# USB0_COMMON_0_VBP2APB_WRAP_CONTROLLER_VBP_CORE_ADDR_MAP register map
Vendor: Texas Instruments
Registers are 32-bit, access per field, reset 0x0 unless marked. A register's access mark holds for its fields unless they carry their own. Offsets are as the file gives them; [hi:lo] are bit positions.

## USB0_COMMON_0_VBP2APB_WRAP_CONTROLLER_VBP_CORE_ADDR_MAP (part 3 of 8)
0x14 VBP2APB_WRAP__CONTROLLER_VBP__CORE_ADDR_MAP_RSVD_6_ASF ro
0x14 VBP2APB_WRAP__CONTROLLER_VBP__CORE_ADDR_MAP_DBOFF ro reset 0x3000
  [31:2] DAO — Doorbell Array Offset, RO. Default = implementation dependent. This field defines the offset in Dwords of the Doorbell Array base address from the Base [i.e. the base address of the xHCI Capability register address space].
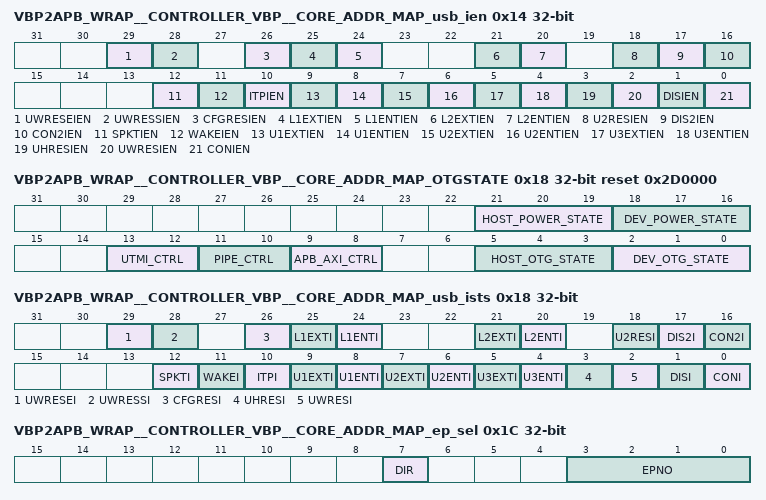
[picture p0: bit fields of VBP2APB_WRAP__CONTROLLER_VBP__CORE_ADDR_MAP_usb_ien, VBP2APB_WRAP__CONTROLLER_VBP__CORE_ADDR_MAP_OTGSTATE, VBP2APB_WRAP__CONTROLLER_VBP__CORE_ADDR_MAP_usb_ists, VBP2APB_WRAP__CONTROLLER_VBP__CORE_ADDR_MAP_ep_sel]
0x14 VBP2APB_WRAP__CONTROLLER_VBP__CORE_ADDR_MAP_usb_ien
  [29] UWRESEIEN rw — End of the USB SS warm reset interrupt enable. This bit enables requesting a UWRESEI interrupt
  [28] UWRESSIEN rw — Start of the USB SS warm reset interrupt enable. This bit enables requesting a UWRESSI interrupt
  [26] CFGRESIEN rw — Configuration reset interrupt enable. This bit enables requesting a CFGRESI interrupt
  [25] L1EXTIEN rw — LPM L1 state exit interrupt enable. This bit enables requesting an L1EXTI interrupt.
  [24] L1ENTIEN rw — LPM L1 state enter interrupt enable. This bit enables requesting an L1ENTI interrupt.
  [21] L2EXTIEN rw — LPM L2 state exit interrupt enable. This bit enables requesting a L2EXTI interrupt.
  [20] L2ENTIEN rw — LPM L2 state enter interrupt enable. This bit enables requesting a L2ENTI interrupt.
  [18] U2RESIEN rw — USB reset [HS/FS mode] interrupt enable. This bit enables requesting an U2RESI interrupt.
  [17] DIS2IEN rw — HS/FS mode disconnection interrupt enable. This bit enables requesting a DIS2I interrupt.
  [16] CON2IEN rw — HS/FS mode connection interrupt enable. This bit enables requesting a CON2I interrupt.
  [12] SPKTIEN rw — Send Custom Packet interrupt enable. This bit enables requesting a Send Custom Packet interrupt.
  [11] WAKEIEN rw — Wakeup interrupt enable. This bit enables requesting a Wakeup interrupt.
  [10] ITPIEN rw — ITP/SOF packet detected interrupt enable. This bit enables requesting an ITPI interrupt.
  [9] U1EXTIEN rw — SS link U1 state exit interrupt enable. This bit enables requesting an U1EXTI interrupt.
  [8] U1ENTIEN rw — SS link U1 state enter interrupt enable. This bit enables requesting an U1ENTI interrupt.
  [7] U2EXTIEN rw — SS link U2 state exit interrupt enable. This bit enables requesting an U2EXTI interrupt.
  [6] U2ENTIEN rw — SS link U2 state enter interrupt enable. This bit enables requesting an U2ENTI interrupt.
  [5] U3EXTIEN rw — SS link U3 state exit interrupt enable [wakeup]. This bit enables requesting an U3EXTI interrupt.
  [4] U3ENTIEN rw — SS link U3 state enter interrupt enable [suspend]. This bit enables requesting an U3ENTI interrupt.
  [3] UHRESIEN rw — USB SS hot reset interrupt enable. This bit enables requesting an UHRESI interrupt.
  [2] UWRESIEN rw — USB SS warm reset interrupt enable. This bit enables requesting an UWRESI interrupt.
  [1] DISIEN rw — SS disconnection interrupt enable. This bit enables requesting a DISI interrupt.
  [0] CONIEN rw — SS connection interrupt enable. This bit enables requesting a CONI interrupt.
0x18 VBP2APB_WRAP__CONTROLLER_VBP__CORE_ADDR_MAP_OTGSTATE ro reset 0x2D0000
  [21:19] HOST_POWER_STATE — Current state of the Host power controlling FSM: 3'b000 : POWER_IDLE 3'b001 : POWER_OFF_ACK 3'b010 : POWER_OFF_MAIN_ACK 3'b011 : POWER_OFF 3'b100 : POWER_ON_REQ 3'b101 : POWER_ISO_DIS 3'b110 : POWER_ON 3'b111 : POWER_ON_READY
  [18:16] DEV_POWER_STATE — Current state of the Device power controlling FSM: 3'b000 : POWER_IDLE 3'b001 : POWER_OFF_ACK 3'b010 : POWER_OFF_MAIN_ACK 3'b011 : POWER_OFF 3'b100 : POWER_ON_REQ 3'b101 : POWER_ISO_DIS 3'b110 : POWER_ON 3'b111 : POWER_ON_READY
  [13:12] UTMI_CTRL — Current state of the USB2 UTMI mux selector. 2'b00 : Both modes off. OTG takes control over UTMI [SRP,BC] 2'b01 : Host active. 2'b10 : Device active. 2'b11 : Illegal [both modes off]
  [11:10] PIPE_CTRL — Current state of the USB3 PIPE mux selector. 2'b00 : Both modes off. 2'b01 : Host active. 2'b10 : Device active. 2'b11 : Illegal [both modes off]
  [9:8] APB_AXI_CTRL — Current state of the ABP/AXI mux selector. 2'b00 : Both modes off. 2'b01 : Host active. 2'b10 : Device active. 2'b11 : Illegal [both modes off]
  [5:3] HOST_OTG_STATE — Current state of the OTG Host FSM. 3'b000 : H_IDLE 3'b001 : H_VBUS_ON 3'b010 : H_VBUS_FAILED 3'b011 : H_OTG_HOST_MODE 3'b100 : H_HOST_MODE 3'b101 : H_SWITCH_TO_DEVICE 3'b110 : H_A_SUSPEND 3'b111 : H_WAIT_VBUS_FALL
  [2:0] DEV_OTG_STATE — Current state of the OTG Device FSM. 3'b000 : DEV_IDLE 3'b001 : DEV_MODE 3'b010 : DEV_SRP 3'b011 : DEV_WAIT_VBUS_FALL 3'b100 : DEV_SWITCH_TO_HOST 3'b101 : DEV_WAIT_FOR_CONN
0x18 VBP2APB_WRAP__CONTROLLER_VBP__CORE_ADDR_MAP_RSVD_7_ASF ro
0x18 VBP2APB_WRAP__CONTROLLER_VBP__CORE_ADDR_MAP_RTSOFF ro reset 0x2000
  [31:5] RRSO — Runtime Register Space Offset, RO. Default = implementation dependent. This field defines the 32-byte offset of the xHCI Runtime Registers from the Base. i.e. Runtime Register Base Address = Base + Runtime Register Set Offset.
0x18 VBP2APB_WRAP__CONTROLLER_VBP__CORE_ADDR_MAP_usb_ists access not given
  [29] UWRESEI — End of the USB warm reset detected. This interrupt is requested after the SuperSpeed warm reset ends. This interrupt is reported on the irqs[0] pin. (access R/W1TC)
  [28] UWRESSI — Start of the USB warm reset detected. This interrupt is requested as soon as the SuperSpeed warm reset signalling is detected. This interrupt is reported on the irqs[0] pin. (access R/W1TC)
  [26] CFGRESI — USB configuration reset detected. This interrupt is requested after the device internally resets its endpoints onfiguration. This is done after each USB reset [UWRESI, UWRESI or U2RESI], after each connection event [CONI, CON2I] and after configuration reset initiated by software [USB_CONF.CFGRST]. Generally this interrupt is generated in the same time as mentioned interrupts, however due to internal clock domain synchronisation this configuration reset can be performed a little later, so one can use this interrupt to perform some software operations. This interrupt informs that controller did the following operations: disabled all non control endpoints, cleared all pending endpoints transfers and interrupts. The configuration reset does not clear general device configuration [set in USB_CONF] and EP0 configuration settings. This interrupt is reported on the irqs[0] pin. (access R/W1TC)
  [25] L1EXTI — LPM L1 state exit detected This interrupt informs that HS/FS LPM exit L1 state. This interrupt is reported on the irqs[0] pin. (access R/W1TC)
  [24] L1ENTI — LPM L1 state enter detected This interrupt informs that HS/FS LPM enter L1 state. This interrupt is reported on the irqs[0] pin. (access R/W1TC)
  [21] L2EXTI — LPM L2 state exit detected This interrupt informs that HS/FS LPM exit L2 state. This interrupt is reported on the irqs[1] pin. (access R/W1TC)
  [20] L2ENTI — LPM L2 state enter detected This interrupt informs that HS/FS LPM enter L2 state. This interrupt is reported on the irqs[0] pin. (access R/W1TC)
  [18] U2RESI — USB reset [HS/FS mode] detected This interrupt is requested after the USB reset in HS/FS mode ends. This interrupt is reported on the irqs[0] pin. (access R/W1TC)
  [17] DIS2I — HS/FS mode disconnection detected This interrupt informs that HS/FS upstream port was disconncted from the USB line. This interrupt is reported on the irqs[0] pin. (access R/W1TC)
  [16] CON2I — HS/FS mode connection detected This interrupt informs that HS/FS upstream port was conncted to the USB line This interrupt is reported on the irqs[0] pin. (access R/W1TC)
  [12] SPKTI — Send Custom Packet This interrupt informs that Custom Packet prepared in the USB_CPKT1-3 registers and triggered with USB_CMD.SPKT bit was already sent. This interrupt is reported on the irqs[0] pin. (access R/W1TC)
  [11] WAKEI — This interrupt informs that at wakeup pin appeared active state. This interrupt is reported on the irqs[1] pin. (access R/W1TC)
  [10] ITPI — ITP/SOF packet detected In SuperSpeed mode this interrupt informs that ITP packet was received. In FS/HS mode this interrupt informs that SOF was detected. This interrupt is reported on the irqs[0] pin. (access R/W1TC)
  [9] U1EXTI — SS link U1 state exit detected This interrupt informs that SuperSpeed link exit U1 state. This interrupt is reported on the irqs[0] pin. (access R/W1TC)
  [8] U1ENTI — SS link U1 state enter detected This interrupt informs that SuperSpeed link enter U1 state. This interrupt is reported on the irqs[0] pin. (access R/W1TC)
  [7] U2EXTI — SS link U2 state exit detected This interrupt informs that SuperSpeed link exit U2 state. This interrupt is reported on the irqs[0] pin. (access R/W1TC)
  [6] U2ENTI — SS link U2 state enter detected This interrupt informs that SuperSpeed link enter U2 state. This interrupt is reported on the irqs[0] pin. (access R/W1TC)
  [5] U3EXTI — SS link U3 state exit detected [wakeup] This interrupt informs that SuperSpeed link exit U3 state. This interrupt is reported on the irqs[1] pin. (access R/W1TC)
  [4] U3ENTI — SS link U3 state enter detected [suspend] This interrupt informs that SuperSpeed link enter U3 state. This interrupt is reported on the irqs[0] pin. (access R/W1TC)
  [3] UHRESI — USB SS hot reset detected This interrupt is requested after the SuperSpeed hot reset ends. This interrupt is reported on the irqs[0] pin. (access R/W1TC)
  [2] UWRESI — USB SS warm reset detected This interrupt is requested after the SuperSpeed warm reset ends or when USBSS-DEVs LTSSM exits Polling.LFPS state. After this reset, SW should reininitialize the controller. This interrupt is reported on the irqs[0] pin. (access R/W1TC)
  [1] DISI — SS disconnection detected This interrupt informs that SuperSpeed link was disconncted from the USB line. This interrupt is reported on the irqs[0] pin. (access R/W1TC)
  [0] CONI — SS connection detected This interrupt informs that SuperSpeed link was conncted to the USB line This interrupt is reported on the irqs[0] pin. (access R/W1TC)
0x1C VBP2APB_WRAP__CONTROLLER_VBP__CORE_ADDR_MAP_RSVD_8_ASF ro
0x1C VBP2APB_WRAP__CONTROLLER_VBP__CORE_ADDR_MAP_HCCPARAMS2 ro reset 0x8
  [3] CTC — This bit indicates whether the xHC USB3 Root Hub ports support the Compliance Transition Enabled [CTE] flag. When this bit is 1 USB3 Root Hub port state machine transitions to the Compliance substate shall be explicitly enabled software. When this bit is 0. USB3 Root Hub port state machine transitions to the Compliance substate are automatically enabled.
0x1C VBP2APB_WRAP__CONTROLLER_VBP__CORE_ADDR_MAP_ep_sel
  [7] DIR rw — Selected Endpoint direction. 0-OUT Endpoint selected, 1-IN Endpoint selected
  [3:0] EPNO rw — Selected Endpoint number
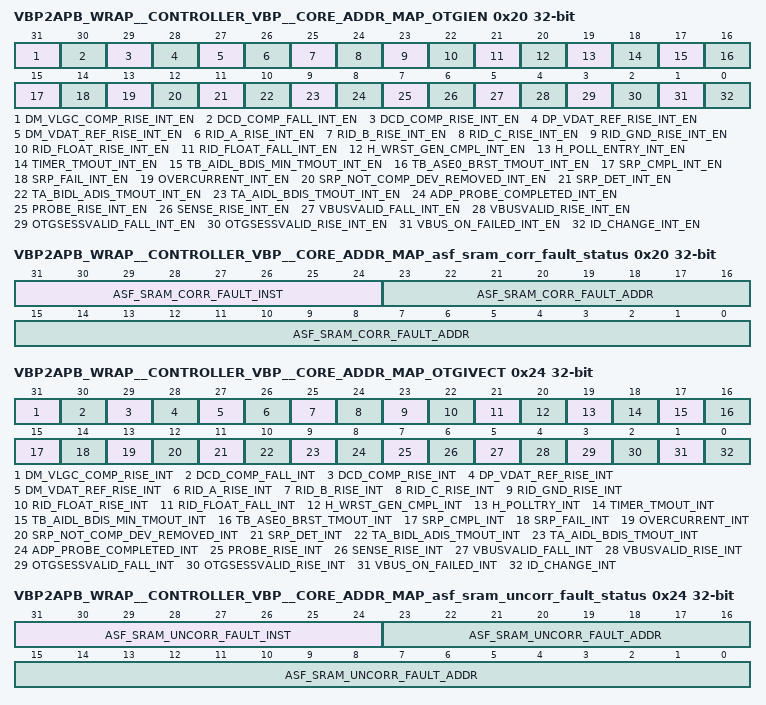
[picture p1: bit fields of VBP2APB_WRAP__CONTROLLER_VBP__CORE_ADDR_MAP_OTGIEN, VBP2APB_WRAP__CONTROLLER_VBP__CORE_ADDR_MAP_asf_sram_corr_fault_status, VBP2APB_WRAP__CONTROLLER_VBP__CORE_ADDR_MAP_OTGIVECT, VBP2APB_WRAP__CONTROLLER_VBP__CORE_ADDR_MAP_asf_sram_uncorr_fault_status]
0x20 VBP2APB_WRAP__CONTROLLER_VBP__CORE_ADDR_MAP_OTGIEN rw
  [31] DM_VLGC_COMP_RISE_INT_EN — DM VLGC comparator rise detect interrupt enable
  [30] DCD_COMP_FALL_INT_EN — DCD comparator fall detect interrupt enable
  [29] DCD_COMP_RISE_INT_EN — DCD comparator rise detect interrupt enable
  [28] DP_VDAT_REF_RISE_INT_EN — DP VDAT comparator rise detect interrupt enable
  [27] DM_VDAT_REF_RISE_INT_EN — DM VDAT comparator rise detect interrupt enable
  [26] RID_A_RISE_INT_EN — RID A comparator rise detect interrupt enable
  [25] RID_B_RISE_INT_EN — RID B comparator rise detect interrupt enable
  [24] RID_C_RISE_INT_EN — RID C comparator rise detect interrupt enable
  [23] RID_GND_RISE_INT_EN — RID GND comparator rise detect interrupt enable
  [22] RID_FLOAT_RISE_INT_EN — RID floating comparator rise detect interrupt enable
  [21] RID_FLOAT_FALL_INT_EN — RID floating comparator detect interrupt enable
  [20] H_WRST_GEN_CMPL_INT_EN — Host Warm Reset generation completed interrupt enable.
  [19] H_POLL_ENTRY_INT_EN — Host Polling state entry interrupt enable.
  [18] TIMER_TMOUT_INT_EN — Timer timeout interrupt enable.
  [17] TB_AIDL_BDIS_MIN_TMOUT_INT_EN — The bus has been in Idle state for the required time during HNP interrupt enable.
  [16] TB_ASE0_BRST_TMOUT_INT_EN — No response from A-Device to HNP interrupt enable.
  [15] SRP_CMPL_INT_EN — SRP completed interrupt enable.
  [14] SRP_FAIL_INT_EN — No response from SRP from A-Device interrupt enable.
  [13] OVERCURRENT_INT_EN — Overcurrent condition detected interrupt enable.
  [12] SRP_NOT_COMP_DEV_REMOVED_INT_EN — Non cmpliant device disconnect interrupt enable
  [11] SRP_DET_INT_EN — SRP pulse detected interrupt enable. NOTE: SRP detection can be enabled only if core is enabled to work as a A-device [OTGSTS.OTG_MODE=0]
  [10] TA_BIDL_ADIS_TMOUT_INT_EN — No activity from B-Device timeout interrupt enable.
  [9] TA_AIDL_BDIS_TMOUT_INT_EN — No response from B-Device for HNP interrupt enable.
  [8] ADP_PROBE_COMPLETED_INT_EN — ADP probe completed interrupt enable
  [7] PROBE_RISE_INT_EN — ADP probe comparator rise detected interrupt enable
  [6] SENSE_RISE_INT_EN — ADP sense comparator rise detected interrupt enable
  [5] VBUSVALID_FALL_INT_EN — Vbusvalid fall detected interrupt enable.
  [4] VBUSVALID_RISE_INT_EN — Vbusvalid fall detected interrupt enable.
  [3] OTGSESSVALID_FALL_INT_EN — Otgsessvalid fall detected interrupt enable.
  [2] OTGSESSVALID_RISE_INT_EN — Otgsessvalid rise detected interrupt enable.
  [1] VBUS_ON_FAILED_INT_EN — Enabling Vbus by A-Device has failed interrupt enable.
  [0] ID_CHANGE_INT_EN — ID change interrupt enable
0x20 VBP2APB_WRAP__CONTROLLER_VBP__CORE_ADDR_MAP_asf_sram_corr_fault_status ro
  [31:24] ASF_SRAM_CORR_FAULT_INST — Last SRAM instance that generated fault.
  [23:0] ASF_SRAM_CORR_FAULT_ADDR — Last SRAM address that generated fault.
0x20 VBP2APB_WRAP__CONTROLLER_VBP__CORE_ADDR_MAP_RSVD_CR ro
0x20 VBP2APB_WRAP__CONTROLLER_VBP__CORE_ADDR_MAP_ep_traddr rw
  [31:0] TRADDR — Transfer Ring address. Address of transfer ring for endpoint selected by endpoint select register. Based on this address, DMA will fetch transfer descriptors from system memory. This register can be used as dequeue pointer. CPU can use this register [read it or write to it] only when endpoint is configured and enabled [using EP_CFG register]
0x24 VBP2APB_WRAP__CONTROLLER_VBP__CORE_ADDR_MAP_OTGIVECT access not given
  [31] DM_VLGC_COMP_RISE_INT — DM VLGC comparator rise detect interrupt (access R/W1TC)
  [30] DCD_COMP_FALL_INT — DCD comparator fall detect interrupt (access R/W1TC)
  [29] DCD_COMP_RISE_INT — DCD comparator rise detect interrupt (access R/W1TC)
  [28] DP_VDAT_REF_RISE_INT — DP VDAT comparator rise detect interrupt (access R/W1TC)
  [27] DM_VDAT_REF_RISE_INT — DM VDAT comparator rise detect interrupt (access R/W1TC)
  [26] RID_A_RISE_INT — RID A comparator rise detect interrupt (access R/W1TC)
  [25] RID_B_RISE_INT — RID B comparator rise detect interrupt (access R/W1TC)
  [24] RID_C_RISE_INT — RID C comparator rise detect interrupt (access R/W1TC)
  [23] RID_GND_RISE_INT — RID GND comparator rise detect interrupt (access R/W1TC)
  [22] RID_FLOAT_RISE_INT — RID floating comparator rise detect interrupt (access R/W1TC)
  [21] RID_FLOAT_FALL_INT — RID floating comparator detect interrupt (access R/W1TC)
  [20] H_WRST_GEN_CMPL_INT — Host Warm Reset generation completed interrupt. (access R/W1TC)
  [19] H_POLLTRY_INT — Host Polling state entry interrupt. (access R/W1TC)
  [18] TIMER_TMOUT_INT — Timer timeout interrupt. (access R/W1TC)
  [17] TB_AIDL_BDIS_MIN_TMOUT_INT — The bus has been in Idle state for the required time during HNP interrupt. (access R/W1TC)
  [16] TB_ASE0_BRST_TMOUT_INT — No response from A-Device to HNP interrupt. (access R/W1TC)
  [15] SRP_CMPL_INT — SRP completed interrupt. (access R/W1TC)
  [14] SRP_FAIL_INT — No response from SRP from A-Device interrupt. (access R/W1TC)
  [13] OVERCURRENT_INT — Overcurrent condition detected interrupt. (access R/W1TC)
  [12] SRP_NOT_COMP_DEV_REMOVED_INT — Not cmpliant device disconnect detect interrupt. (access R/W1TC)
  [11] SRP_DET_INT — SRP pulse detected interrupt. (access R/W1TC)
  [10] TA_BIDL_ADIS_TMOUT_INT — No activity from B-Device timeout interrupt. (access R/W1TC)
  [9] TA_AIDL_BDIS_TMOUT_INT — No response from B-Device for HNP interrupt. (access R/W1TC)
  [8] ADP_PROBE_COMPLETED_INT — ADP completed. Status is reported in OTGADPSTS register. (access R/W1TC)
  [7] PROBE_RISE_INT — ADP probe comparator rise detected interrupt (access R/W1TC)
  [6] SENSE_RISE_INT — ADP sense comparator rise detected interrupt (access R/W1TC)
  [5] VBUSVALID_FALL_INT — Vbusvalid fall detected interrupt. (access R/W1TC)
  [4] VBUSVALID_RISE_INT — Vbusvalid fall detected interrupt. (access R/W1TC)
  [3] OTGSESSVALID_FALL_INT — Otgsessvalid fall detected interrupt. (access R/W1TC)
  [2] OTGSESSVALID_RISE_INT — Otgsessvalid rise detected interrupt. (access R/W1TC)
  [1] VBUS_ON_FAILED_INT — Enabling Vbus by A-Device has failed. This bit should be cleared before enabling subsequent connection as host. (access R/W1TC)
  [0] ID_CHANGE_INT — ID change interrupt (access R/W1TC)
0x24 VBP2APB_WRAP__CONTROLLER_VBP__CORE_ADDR_MAP_asf_sram_uncorr_fault_status ro
  [31:24] ASF_SRAM_UNCORR_FAULT_INST — Last SRAM instance that generated fault.
  [23:0] ASF_SRAM_UNCORR_FAULT_ADDR — Last SRAM address that generated fault.
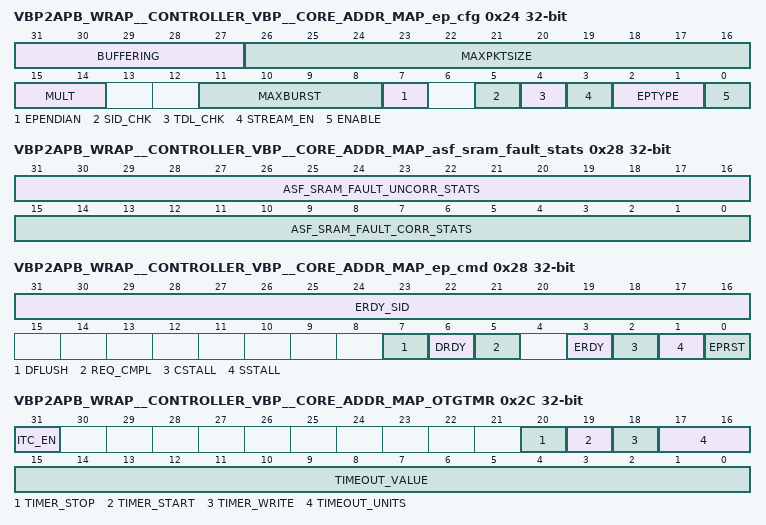
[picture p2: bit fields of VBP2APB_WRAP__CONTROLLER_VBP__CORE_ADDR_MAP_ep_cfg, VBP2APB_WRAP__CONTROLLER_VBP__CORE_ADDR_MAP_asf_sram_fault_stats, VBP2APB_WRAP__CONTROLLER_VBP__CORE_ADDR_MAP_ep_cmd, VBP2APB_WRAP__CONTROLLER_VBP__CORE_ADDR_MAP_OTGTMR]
0x24 VBP2APB_WRAP__CONTROLLER_VBP__CORE_ADDR_MAP_ep_cfg
  [31:27] BUFFERING rw — Max number of buffered packets. The maximum number of packets the device can buffer in the on-chip memory for a specified endpoint. Valid values are from 0 to 15. Value 0 means that 1 on-chip buffer is available for the appropriate endpoint. Value 15 means that 16 on-chip buffers are available for the appropriate endpoint. Each IN endpoint has individual buffers associated with it. OUT endpoints have common buffers, so buffering for OUT endpoints is determined by the maximum buffering value along all enabled OUT endpoints. The number of possible endpoint buffers depends on the on-chip memory size and the size of endpoint buffers.
  [26:16] MAXPKTSIZE rw — Max packet size. The maximum packet size this endpoint is capable of sending or receiving. SuperSpeed mode: For control endpoints, this field is set to 512. For bulk endpoint types, this field is set to 1024. For interrupt and isochronous endpoints, this field is set to 1024 if this endpoint defines a value in the bMaxBurst field greater than zero. If the value in the bMaxBurst field is set to zero, then this field can have any value from 0 to 1024 for an isochronous endpoint, and 1 to 1024 for an interrupt endpoint. High Speed/Full Speed mode: For control endpoints, this field is set to 64. For other endpoint types this field can have any value from 0 to 1024.
  [15:14] MULT rw — ISO max burst SuperSpeed mode: A zero-based value that indicates the maximum number of bursts within a service interval that this endpoint supports. This field is only valid for isochronous endpoints. A value of zero indicates that the device supports one Burst of bMaxBurst packets per service interval. The max value that can be set in this field in SuperSpeed is '2'. HS/FS mode: This field indicates how many packets will be transferred during micro frame. In Full-Speed mode only one ISO IN packet can be transferred per endpoint, per frame, thus this field has to be always '0'. In High-Speed mode, up to three ISO IN packets can be transferred per endpoint, per microframe, so the max value that can be set in this field in HighSpeed is '2'.
  [11:8] MAXBURST rw — Maximum Burst size. The maximum number of packets the endpoint can send or receive as part of a burst. Valid values are from 0 to 15. A value of 0 indicates that the endpoint can only burst one packet at a time, and a value of 15 indicates that the endpoint can burst up to 16 packets at a time. For endpoints of type control this is set to 0. This field is meaningfull only in SuperSpeed mode.
  [7] EPENDIAN rw — DMA transfer endianness. When the conversion is ON, the byte order within DWORD is inverted. While the bit is set, the software confirms that the transfer length is a multiplication of 4 bytes. Enabling the conversion is possible only when SUPPORT_ENDIANESS_CONV is defined. By default this parameter is not defined, so endianess conversion is disabled. 0: Endianess conversion OFF 1: Endianess conversion ON
  [5] SID_CHK rw — SID check[only in SS mode for BULK OUT EP] This field can be set only for SS bulk OUT endpoints with stream support enabled 1] If SID_CHK bit is set, the device checks whether the incoming packets from the host to the particular OUT endpoint have the SID field set to the expected value. If the packet has an expected SID value is then taken and stored in the on-chip device buffers. If the packet has a different SID than expected, then the packet is rejected [NRDY] and the SIDERROR interrupt is reported to the software. The value of the SID to which incoming packets will be compared, are written to the device during sending ERDY TP [EP_CMD.ERDY and EP_CMD.ERDY_SID]. The SID value from the incoming packet that has been rejected and caused the SIDERR interrupt can be read from the EP_STS_SID register. 2] If SID_CHK bit is not set, then each packet from the host is taken to the on-chip buffers is transmitted by the DMA regardless of the SID field in the TD. 0: SID chceck at device input OFF 1: SID chceck at device input ON
  [4] TDL_CHK rw — TDL check[only in SS mode for BULK OUT EP]. This field has to be set for stream capable SS bulk endpoints and it can be set for other bulk endpoint. The OUT bulk endpoints If the TDL_CHK bit is set if the device takes the packets to the OUT endpoint only when the value of the TDL [EP_CMD.TDL] for this endpoint is different from zero. Each received packet for the particular endpoint decrements the value of a TDL. If the TDL_CHK bit is not set, then each packet from the host to the OUT endpoint is taken as long as it free space in the on-chip device buffers. The IN bulk endpoints This bit is is used by USBSS_DEV to set EOB bit when TDL [programmed value] reach zero. 0: Do not check the TDL value when sending/receiving packets to the endpoints 1: Check the TDL value when sending/receiving packets to the endpoint
  [3] STREAM_EN rw — Stream support enable [only in SS mode]. This bit must be set to enable a stream transfes on a bulk endpoint 0: Stream support OFF 1: Stream support ON
  [2:1] EPTYPE rw — Endpoint type. 0: control, 1: isochronous, 2: bulk, 3: interrupt. Endpoint type is programmable, however, certain types of transmissions require hardware support that must be incorporated prior to implementation. That can be done only for selected endpoints. Selective inclusion of hardware support is to reduce the size of the controller. Accordingly: - Endpoint-type iso should be set by the software only for those endpoints for which isochronous transmission hardware support is enabled. - A bulk endpoint can handle transmission with Bulk Streams support only for those endpoints for which Bulk Stream transmission hardware support is enabled. For detailed description how to implement hardware support for ISO transfers or Bulk Stream transfers see chapter 'Endpoints Implementation'.
  [0] ENABLE rw — Endpoint enable. If endpoint is disabled [the ENABLE bit is cleared], the endpoint will not: - request any interrupts - start any transmission over the DMA Even if Endpoint is disabled, software can set DRDY bit for it, but the DMA transmission will not begin until the endpoint is enabled. 0: disabled 1: enabled Reset value of this bit for EP0 is 1, for other EP's is 0.
0x28 VBP2APB_WRAP__CONTROLLER_VBP__CORE_ADDR_MAP_CLK_FREQ reset 0x200000
  [31:16] CLK_FREQ_KHZ rw — CLK_FREQ_KHZ defines how many cycles are needed to determine 1 ms clock base for stb_clk_predft. Example: Let's say that stb_clk_predft frequency is 32kHz. With CLK_FREQ_KHZ set to 32 time base would be 32 cycles of 32khz clock which gives 1 ms
0x28 VBP2APB_WRAP__CONTROLLER_VBP__CORE_ADDR_MAP_asf_sram_fault_stats access not given
  [31:16] ASF_SRAM_FAULT_UNCORR_STATS — Count of number of uncorrectable errors if implemented. Count value will saturate at 0xffff. (access R/W1TC)
  [15:0] ASF_SRAM_FAULT_CORR_STATS — Count of number of correctable errors if implemented. Count value will saturate at 0xffff. (access R/W1TC)
0x28 VBP2APB_WRAP__CONTROLLER_VBP__CORE_ADDR_MAP_ep_cmd access not given
  [31:16] ERDY_SID rw — ERDY Stream ID value [used in SS mode]. This field contains SID - it will be sent to host in ERDY packet [by writing '1' to ERDY]. This field is meaningfull only in SuperSpeed mode.
  [7] DFLUSH rw — Data flush. Writing '1' to this bit performs the following actions for particular endpoint: - clears DRDY bit and stops DMA transfer - flush endpoint data from on chip buffers As in case of Endpoint reset [EPRST bit], after endpoint data flush the software is responsible for it to re-set the Endpoint TRADDR. When DFLUSH operation is started ['1' is written], CPU must wait until this bit becomes again '0' [it indicates that HW finishes all internal opertations related to DFLUSH], and only then can proceed with next software operations. Writing '0' has no effect.
  [6] DRDY rw — Transfer descriptor ready. Transfer Descriptor Ready for selected endpoint [0 - no effect, 1 - starts transfer]. Writing '1' to this bit informs USBSS-DEV that in-system memory has prepared a new Transfer Descriptor for selected endpoints. If an IN endpoint is 'Not Ready' [NRDY=1 in Endpoint Status Register], then setting the DRDY bit [which is proceeded by DMA transfer to the on-chip buffers] will cause the device to send the ERDY packet. If the TRB error occurs, the DRDY bit is cleared and held in the low state until the TRBERR is not cleared [even if the DTRANS bit is set i.e. the Multiple TRB chain mode is enabled]. This bit is duplicated in the Doorbell register. Writing '1' to this bit while DESCMIS interrupt flag is set for the same endpoint will also clear the DESCMIS flag.
  [5] REQ_CMPL rw — Request complete. 0 : no effect 1 : informs device that Request service is complete Bit valid only for endpoint 0. Writing '1' to this bit informs USBSS-DEV that software finished USB request service and device can send ACK answer for the Status Stage within USB request. This bit is automatically cleared by USBSS-DEV after device answers to the status stage with ACK or STALL. Until software do not set this bit, during proceeding current host request, the device will answer to the status stage with NRDY answer.
  [3] ERDY rw — Send ERDY TP. Writing '1' to this bit forces the device to send ERDY TP with stream ID equal to ERDY_SID. This bit is necessary to support SS bulk stream transfers. This bit is also used during control transfers [in both modes: HS/FS and SS]: writing '1' instruct device controller HW that it can exit from Setup Stage to the Data Stage [or directly to the Status Stage if USB Request is without Data Stage]. However the ERDY packet is only actually sent in SS mode. Writing '0' has no effect.
  [2] CSTALL — Endpoint STALL clear. Writing '1' to this bit cause the endpoint becames not halted. 0: no effect 1: clears endpoint STALL (access R/W1TC)
  [1] SSTALL rw — Endpoint STALL set. Writing '1' to this bit cause the endpoint is halted. 0: no effect 1: STALLs endpoint
  [0] EPRST rw — Endpoint reset. 0: no effect 1: resets endpoint This command performs the following actions for particular endpoint: - clears DRDY bit and stops DMA transfer - clears on-chip buffers - clears sequence number in SS mode or Data Toggle in HS/FS mode This command does not clear Endpoint interrupt if already requested [irq[0] pin was asserted] thus it is recommended first to clear all interrupts from endpoint scheduled to reset. When EPRST operation is started ['1' is written], CPU must wait until this bit becomes again '0' [it indicates that HW finishes all internal opertations related to DFLUSH], and only then can proceed with next software operations. Additionally, when DMA already started processing TD for this EP, the EPRST command cause that DMA engine will once more access the descriptor in external memory. After endpoint reset the software is responsible for it to re-set the Endpoint TRADDR. Writing '0 'has no effect.
0x2C VBP2APB_WRAP__CONTROLLER_VBP__CORE_ADDR_MAP_OTGTMR
  [31] ITC_EN wo — ITC ENABLE for device mode 0 - Device IOC and ISP interrupts moderation by OTG_IVECT interrupt from OTGTMR is disabled. 1 - The OTGTMR is used for Device IOC and ISP interrupts moderation. The OTG_IVECT from OTGTMR is not requested.
  [20] TIMER_STOP wo — Stop timer
  [19] TIMER_START wo — Start timer
  [18] TIMER_WRITE wo — Timer value and units write strobe
  [17:16] TIMEOUT_UNITS wo — Time units: 0 - hundreds of microseconds [valid only if otg controller clock is in MHz range] 1 - milliseconds 2 - tens of milliseconds 3 - hundreds of milliseconds Valid only if TIMER_WRITE is 1.
  [15:0] TIMEOUT_VALUE wo — Timeout value for timer. Valid only if TIMER_WRITE is 1.
0x2C VBP2APB_WRAP__CONTROLLER_VBP__CORE_ADDR_MAP_RSVD_12_ASF ro
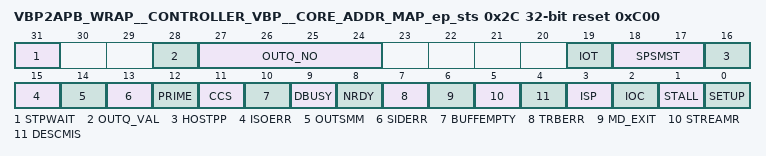
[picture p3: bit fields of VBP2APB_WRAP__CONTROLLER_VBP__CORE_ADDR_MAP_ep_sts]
0x2C VBP2APB_WRAP__CONTROLLER_VBP__CORE_ADDR_MAP_ep_sts access not given reset 0xC00
  [31] STPWAIT — Bit used only for EP0. If setup packet is received correctly and stored in the on-chip buffer, this bit is set to 1 and interrupt is generated. Setup packet is applicable only to control transmissions [EP0]. This interrupt can be masked by the corresponding bit in EP_STS_EN register. Writing '1' to this bit clears the interrupt. (access R/W1TC)
  [28] OUTQ_VAL ro — OUT queue valid flag. This field indicates whether the endpoint number of the OUT packet waiting for transmission by the DMA, is valid or not. In other words, whether the packet queue is not empty. As there is one buffers queue for all Out Endpoints, this field is not endpoint related, and thus it can be read regardless of current value stored in the EP_SEL register. 0 - queue of out packets is empty thus OUTQ_NO is not valid 1 - queue of out packets is not empty thus OUTQ_NO is valid This bit is only a status bit [not an interrupt flag].
  [27:24] OUTQ_NO ro — OUT queue endpoint number. This field shows the number of the endpoint to which the packet, received by the host, currently is waiting to be transmitted by the DMA from the on-chip buffers to the system memory. As there is one buffers queue for all Out Endpoints, this field is not endpoint related, and thus it can be read regardless of current value stored in the EP_SEL register. This bit is only a status bit [not an interrupt flag].
  [19] IOT — Interrupt On Transfer complete. This interrupt is generated when the TDL is decremented to zero. It means that the device - does not expect to have more packets from the host [OUT EP] - does not want to send more packets [IN EP] More information can be found in the description of EP_TDL register. Writing '1' to this bit clears the interrupt. (access R/W1TC)
  [18:17] SPSMST ro — Stream Protocol State Machine State [only for Bulk stream endpoints] This field is valid only for stream capable bulk endpoints and reflects the current state of the Stream Protocol State Machine for selected endpoint: 0 - DISABLED 1 - IDLE 2 - START_STREAM 3 - MOVE_DATA Soft should check if the SPSM is in IDLE state before sending ERDY TP from stream EP [leading to the transition from IDE to START_STREAM] Before software will order to send an ERDY TP from stream capable endpoint [leading to the transition from IDLE to START_STREAM] it should first check if the SPSM is in IDLE state. This bit is only a status bit [not an interrupt flag].
  [16] HOSTPP ro — Host Packet Pending [only for SS mode]. Depending on whether the endpoint is enabled for streams or not, this bit behaves as follows: 1]For stream enabled bulk endpoints [EP_CFG.EPSTREAM_EN bit set]: This bit reflects the PP bit in the last packet received from the host during Move Data state of the DOSPSM for the OUT endpoint. This bit is updated on exit from the MOVE DATA state of the DOSPSM and can be analyzed during servicing MD_EXIT interrupt for BULK OUT endpoint with Stream support enabled. If this bit is set to '0' during MD_EXIT interrupt, it means that the host terminated current stream. If this bit is set to '1' during MD_EXIT interrupt, it means that the host doesn't terminated current stream and still has data for this stream. 2]Non stream bulk endpoints [EP_CFG.EPSTREAM_EN bit not set]: This bit reflects the PP bit in the packets received from the host. This bit is updated as long as the EP_CMD.TDL is nonzero and it can be analyzed during servicing IOT interrupt for BULK endpoints. This bit is only a status bit [not an interrupt flag].
  [15] ISOERR — ISO transmission error. Error of isochronous transmission. This bit is set during data transmission to/from ISO endpoints while the last data transfer at PIPE IF is in current micro frame. For ISO IN endpoints: If host asks for data packet and device is not ready for sent data immediatelly, then ISOERR flag is set for particular endpoint and core sends a 0-length DATA packet to the host. The next data portion transfer [for the next micro frame] from system memory to on-chip buffers is automatically started [when EP_CMD.DRDY bit is set or DMA works in DMULT mode]. For ISO OUT endpoints: When host issues an OUT data packet for the specific endpoint but the OUT buffers are full, then device is unable to receive data packet and the ISOERR flag is set. For more information about ISO trasfer see chapter 'Isochronous Transfers'. This interrupt can be masked by the corresponding bit in EP_STS_EN register. Writing '1' to this bit clears the interrupt. (access R/W1TC)
  [14] OUTSMM — OUT size mismatch. This bit is set when host sends a different data size than device was anticipating [according to Data Length field in TRB]. In such a case, the DMA updates length field in current TRB, updates TRADDR [next TRB address], and triggers the interrupt. DMA will not start processing TRB ring of this EP until its DRDY is set. This interrupt can be masked by the corresponding bit in EP_STS_EN register. Writing '1' to this bit clears the interrupt. (access R/W1TC)
  [13] SIDERR — Stream error [used only in SS mode] If host requested IN [sent OUT] packet with particular Stream ID, and device is actually programmed to transfer packets with different Stream ID [SID written in the EP_CMD.ERDY_SID field] the host IN request [OUT packet] is rejected [NRDY] and the SIDERR interrupt is requested. In case of IN direction, the SIDERR interrupt will not be requested when device is not prepared for any transfer [EP_CMD.TDL= 0 for this endpoint]. In this case [and additionally when EP_CMD.DRDY= 0 and EP_STS.DBUSY=0], the DESCMIS interrupt will be requested. This interrupt can be masked by the corresponding bit in EP_STS_EN register. Writing '1' to this bit clears the interrupt. (access R/W1TC)
  [12] PRIME — Prime [used only in SS mode]. This bit is set when the device receives the packet with PRIME ID. This interrupt can be masked by the corresponding bit in EP_STS_EN register. Writing '1' to this bit clears the interrupt. (access R/W1TC)
  [11] CCS ro — Current Cycle Status. Informs about current value of C bit corresponding to DMA ownership of TRBs for selected endpoint. For more information about TRBs C bit see chapter 2.11.3. This bit is only a status bit [not an interrupt flag].
  [10] BUFFEMPTY ro — Endpoint Buffer Empty. When this bit is set to '1', there are no packets for the particular endpoint in the on-chip buffers. This bit is only a status bit [not an interrupt flag].
  [9] DBUSY ro — DMA busy. This bit is set to '1' while the DMA services the endpoint. Through the service means either actual transmission of data between on-chip cache and system memory for particular endpoint or a pending data transmission which has already begun but was interrupted by endpoint with a higher priority. Such pending transmissions will begin automatically themselves after these higher priority. This bit is only a status bit [not an interrupt flag].
  [8] NRDY — Not ready [used only in SS mode]. This bit is automatically set to 1 when for some reason endpoint enters Flow Control. If ERDY is sent automatically by the endpoint [what is done when current TDL value is greater then zero], this interrupt bit is not automatically cleared [although the endpoint itself leaves FlowControl]. Note: For BULK OUT endpoints with TDL_CHK bit seting this interrupt should be used instead of DESCMIS interrupt. See also DESCMIS description. Writing '1' to this bit clears the interrupt. (access R/W1TC)
  [7] TRBERR — TRB error. This bit is set if DMA read corrupted TRB [wrong C bit value or TRB type]. Address of the TRB is stored in the EP_TRADDR register. This interrupt can be masked by the corresponding bit in EP_STS_EN register. If this error occurs, the bit DRDY is cleared and held in the low state until the TRBERR is not cleared. To start the DMA again, the software has to clear this interrupt and set the DRDY bit once more. Writing '1' to this bit clears the interrupt. (access R/W1TC)
  [6] MD_EXIT — EXIT from MOVE DATA State [used only for stream transfers in SS mode] This bit is set to '1' if stream capable endpoint exits from MOVE DATA state of Bulk IN/OUT Stream Ptrotocol State Machine [ISPSM/OSPSM]. Stream support is class-dependent. This interrupt can be masked by the corresponding bit in MD_EXITEN register. Writing '1' to this bit clears the interrupt. (access R/W1TC)
  [5] STREAMR — Stream Rejected [used only in SS mode]. This bit is set to '1' if device tries to initiate stream number and host does not accept it. Stream support is class-dependent. This interrupt can be masked by the corresponding bit in STREAMREN register. Writing '1' to this bit clears the interrupt. (access R/W1TC)
  [4] DESCMIS — Transfer descriptor missing. This bit is set to 1 and interrupt is generated when any of the following conditions are met: - device is requested to send data to host and none of Transfer Descriptor is prepared [IN transfer] - device receives OUT packet and cannot transmit it using DMA as Transfer Descriptor has not been prepared [DRDY was not set] for it [OUT transfer] Note1: This interrupt is not generated for ISO IN endpoints. For such endpoints the ISOERR interrupt should be used. Note2: DMA will not start operating on transfer descriptor array until the OUT packet is received [or host requests IN packet] and processor has not previously notified DMA [by writing to EP_CMD register of DRDY register]. Note2: For BULK OUT endpoints with TDL_CHK bit set this interrupt will not by requested as device will not accept any packet from host when TRB is not prepared [and TDL is not written with non-zero value]. In this case the NRDY interrupt should be used instead of DESMIS. Writing '1' to this bit or writing '1' to EP_CMD.DRDY bit of endpoints which generated interrupt will delete the interrupt. This interrupt can be masked by the corresponding bit in EP_STS_EN register. Writing '1' to this bit clears the interrupt. (access R/W1TC)
  [3] ISP — Interrupt on Short Packet. This bit is set to 1 and interrupt is generated when a transfer containing less data than MaxPacket for a given endpoint has been completed and transfer descriptor has been updated.Enabling or disabling of interrupt is realized by ISP bit in transfer descriptor. Additionally, this interrupt can be masked for a particular endpoint in EP__ISTS register. When in given transfer descriptor both interrupts are enabled [IOC and ISP], then in the case of short packet only one interrupt is generated - SP. Writing '1' to this bit clears the interrupt. (access R/W1TC)
  [2] IOC — Interrupt On Complete When DMA transfer is completed and transfer descriptor is updated, then this bit is set to 1 and interrupt is generated. Enabling or disabling of this interrupt is realized by IOC bit in transfer descriptor. Additionally, this interrupt can be masked for a particular endpoint in EP__ISTS register. When in given transfer descriptor both interrupts [IOC and ISP interrupts] are enabled, then in the case of short packet, only one interrupt is generated - SP. Writing '1' to this bit clears the interrupt. (access R/W1TC)
  [1] STALL ro — Endpoint STALL status 0 - endpoint is not stalled 1 - endpoint is stalled This bit is not treated as an interrupt [not reported in the EP__ISTS register]. This bit is read-only.
  [0] SETUP — Setup transfer complete. Bit used only for EP0. If setup type transmission has been completed and data from host has been received and copied to system memory, this bit is set to '1' and interrupt is generated. Setup packet is applicable only to control transmissions [EP0]. This interrupt can be masked by the corresponding bit in EP_STS_EN register. Writing '1' to this bit clears the interrupt. (access R/W1TC)
